AUTOSAR XML (schema 00044)
package /E40_Platform_System_SystemPackage/Components
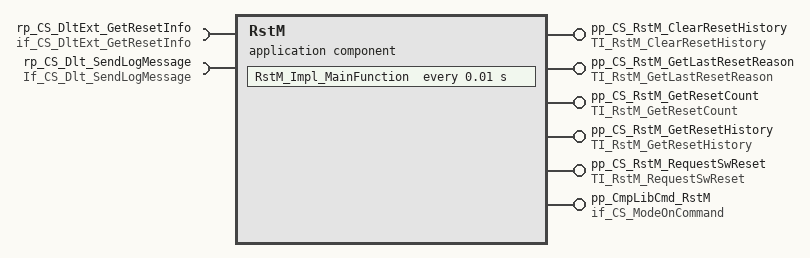
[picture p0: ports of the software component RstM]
  application sw component type RstM
    5 x provide port:
      pp_CS_RstM_ClearResetHistory: server-com-spec{operation=RstM_ClearResetHistory, queue-length=1}, provided-interface=TI_RstM_ClearResetHistory
      pp_CS_RstM_GetLastResetReason: server-com-spec{operation=RstM_GetLastResetReason, queue-length=1}, provided-interface=TI_RstM_GetLastResetReason
      pp_CS_RstM_GetResetCount: server-com-spec{operation=RstM_GetResetCount, queue-length=1}, provided-interface=TI_RstM_GetResetCount
      pp_CS_RstM_GetResetHistory: server-com-spec{operation=RstM_GetResetHistory, queue-length=1}, provided-interface=TI_RstM_GetResetHistory
      pp_CS_RstM_RequestSwReset: server-com-spec{operation=RstM_RequestSwReset, queue-length=1}, provided-interface=TI_RstM_RequestSwReset
    require port rp_CS_DltExt_GetResetInfo: client-com-spec=GetResetInfo, required-interface=if_CS_DltExt_GetResetInfo
    require port rp_CS_Dlt_SendLogMessage: client-com-spec=SendLogMessage, required-interface=If_CS_Dlt_SendLogMessage
    provide port pp_CmpLibCmd_RstM: server-com-spec{operation=Impl_OnCommand, queue-length=1}, provided-interface=if_CS_ModeOnCommand
    behavior IB_RstM
      5 x operation invoked event:
        OIE_pp_CS_RstM_GetLastResetReason_RstM_GetLastResetReasonTrigByRstM_GetLastResetReason: start-on-event=RstM_GetLastResetReason, operation=pp_CS_RstM_GetLastResetReason.RstM_GetLastResetReason
        OIE_pp_CS_RstM_GetResetCount_RstM_GetResetCountTrigByRstM_GetResetCount: start-on-event=RstM_GetResetCount, operation=pp_CS_RstM_GetResetCount.RstM_GetResetCount
        OIE_pp_CS_RstM_RequestSwReset_RstM_RequestSwResetTrigByRstM_RequestSwReset: start-on-event=RstM_RequestSwReset, operation=pp_CS_RstM_RequestSwReset.RstM_RequestSwReset
        OIE_pp_CS_RstM_ClearResetHistory_RstM_ClearResetHistoryTrigByRstM_ClearResetHistory: start-on-event=RstM_ClearResetHistory, operation=pp_CS_RstM_ClearResetHistory.RstM_ClearResetHistory
        OIE_pp_CS_RstM_GetResetHistory_RstM_GetResetHistoryTrigByRstM_GetResetHistory: start-on-event=RstM_GetResetHistory, operation=pp_CS_RstM_GetResetHistory.RstM_GetResetHistory
      timing event TERstM_Impl_MainFunction: start-on-event=RstM_Impl_MainFunction, period=0.01
      operation invoked event OIE_pp_CmpLibCmd_RstM_RstM_Impl_OnCommandTrigByImpl_OnCommand: start-on-event=RstM_Impl_OnCommand, operation=pp_CmpLibCmd_RstM.Impl_OnCommand
      port-api-options:
        enable-take-address=false, indirect-api=false, port=pp_CS_RstM_ClearResetHistory
        enable-take-address=false, indirect-api=false, port=pp_CS_RstM_GetLastResetReason
        enable-take-address=false, indirect-api=false, port=pp_CS_RstM_GetResetCount
        enable-take-address=false, indirect-api=false, port=pp_CS_RstM_GetResetHistory
        enable-take-address=false, indirect-api=false, port=pp_CS_RstM_RequestSwReset
        enable-take-address=false, indirect-api=false, port=rp_CS_DltExt_GetResetInfo
        enable-take-address=false, indirect-api=false, port=rp_CS_Dlt_SendLogMessage
        enable-take-address=false, indirect-api=false, port=pp_CmpLibCmd_RstM
      7 x runnable, all with can-be-invoked-concurrently=true:
        RstM_GetLastResetReason
        RstM_GetResetCount
        RstM_GetResetHistory
        RstM_RequestSwReset
        RstM_ClearResetHistory
        RstM_Impl_MainFunction
        RstM_Impl_OnCommand
  swc implementation IMPL_RstM: behavior=IB_RstM
